# IME3_ICONT register map
Vendor: Texas Instruments
Peripheral module from a debugger description file (folder DRA75x_DRA74x).
Registers are 32-bit, read-write, no defined reset value unless marked. A register's access mark holds for its fields unless they carry their own. Offsets are as the file gives them; lines under a group give offsets from that group; [hi:lo] are bit positions; {n}, {i} and the like mark numbered series; 'fields as' and 'values as' point back to an identical list; <NAME> marks a mode.

## IME3_ICONT
0x00 IME3_REVISION ro — IP Revision Identifier (X.Y.R) Used by software to track features, bugs, and compatibility
  [31:0] REVISION — IP Revision
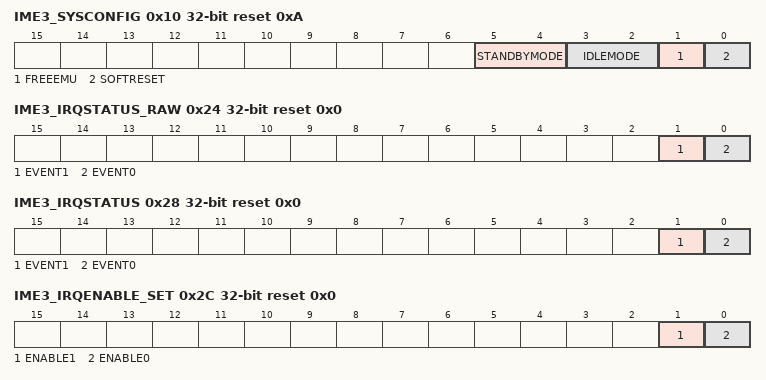
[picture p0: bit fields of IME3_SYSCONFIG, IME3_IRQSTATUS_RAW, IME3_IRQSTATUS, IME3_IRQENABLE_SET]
0x10 IME3_SYSCONFIG access per field reset 0xA — Clock management configuration
  [5:4] STANDBYMODE ro — Configuration of the local initiator state management mode. By definition, initiator may generate read/write transaction as long as it is out of STANDBY state.
    0=Force-standby mode: local initiator is unconditionally placed in standby state. Backup mode, for debug only.
  [3:2] IDLEMODE rw — Configuration of the local target state management mode. By definition, target can handle read/write transaction as long as it is out of IDLE state.
    0=Force-idle mode: local target's idle state follows (acknowledges) the system's idle requests unconditionally, that is, regardless of the IP module's internal requirements. Backup mode, for debug only.; 1=no (No-idle mode: local target never enters idle state. Backup mode, for debug only.); 2=Smart-idle mode: local target's idle state eventually follows (acknowledges) the system's idle requests, depending on the IP module's internal requirements. IP module shall not generate (IRQ- or DMA-request-related) wakeup events.; 3=smartwakeup (Smart-idle wakeup-capable mode: local target's idle state eventually follows (acknowledges) the system's idle requests, depending on the IP module's internal requirements. IP module may generate (IRQ- or DMA-request-related) wakeup events when in idle state. Mode is only relevant if the appropriate IP module 'swakeup' output(s) is (are) implemented.)
  [1] FREEEMU ro — Sensitivity to emulation (debug) suspend input signal.
    1=insensitive (IP module is not sensitive to emulation suspend)
  [0] SOFTRESET rw — Software reset. (Optional)
    0=done (Reset done, no pending action); 0=No_action; 1=pending (Initiate software reset); 1=Reset_(software_or_other)_ongoing
0x20 IME3_IRQ_EOI wo reset 0x0 — End Of Interrupt number specification
  [31:0] RESERVED — Write value should be zero.
0x24 IME3_IRQSTATUS_RAW access not given reset 0x0 — Per-event raw interrupt status vector, line #0. Raw status is set even if event is not enabled. Write 1 to set the (raw) status, mostly for debug.
  [1] EVENT1 — Settable raw status for event #1 (Gen_It) (access RW W1toSet)
    0=noevent (No action); 0=pending (No event pending); 1=set (Event pending); 1=Set_event_(debug)
  [0] EVENT0 — Settable raw status for event #0 (End_Pgm) (access RW W1toSet)
    values as EVENT1
0x28 IME3_IRQSTATUS access not given reset 0x0 — Per-event 'enabled' interrupt status vector, line #0. Enabled status is not set unless event is enabled. Write 1 to clear the status after interrupt has been serviced (raw status gets cleared, that is, even if not enabled).
  [1] EVENT1 — Clearable, enabled status for event #1 (Gen_it) (access RW W1toClr)
    0=noevent (No action); 0=pending (No (enabled) event pending); 1=clear (Event pending); 1=Clear_(raw)_event
  [0] EVENT0 — Clearable, enabled status for event #0 (End_Pgm) (access RW W1toClr)
    values as EVENT1
0x2C IME3_IRQENABLE_SET access not given reset 0x0 — Per-event interrupt enable bit vector, line #0. Write 1 to set (enable interrupt). Readout equal to corresponding _CLR register.
  [1] ENABLE1 — Enable for event #1 (Gen_It) (access RW W1toSet)
    0=disabled (No action); 0=Interrupt_disabled_(masked); 1=enabled (Interrupt enabled); 1=Enable_interrupt
  [0] ENABLE0 — Enable for event #0 (End_Pgm) (access RW W1toSet)
    values as ENABLE1
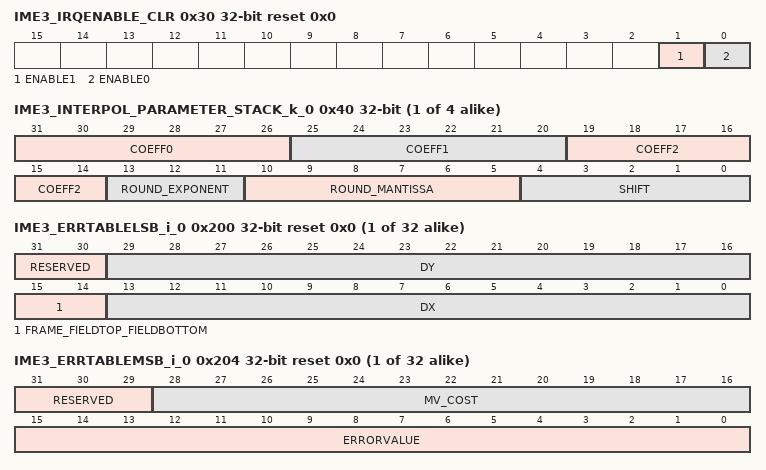
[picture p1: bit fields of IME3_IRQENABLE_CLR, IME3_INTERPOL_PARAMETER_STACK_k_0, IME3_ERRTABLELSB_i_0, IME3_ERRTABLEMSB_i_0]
0x30 IME3_IRQENABLE_CLR access not given reset 0x0 — Per-event interrupt enable bit vector, line #0. Write 1 to clear (disable interrupt). Readout equal to corresponding _SET register.
  [1] ENABLE1 — Enable for event #1 (Gen_It) (access RW W1toClr)
    0=disabled (No action); 0=Interrupt_disabled_(masked); 1=enabled (Interrupt enabled); 1=Disable_interrupt
  [0] ENABLE0 — Enable for event #0 (End_Pgm) (access RW W1toClr)
    values as ENABLE1
{0x40+4i} IME3_INTERPOL_PARAMETER_STACK_k_{i} (i=0..3) — Interpolation Filter Pass Configuration
  [31:26] COEFF0 — Coefficient vector
  [25:20] COEFF1 — Coefficient vector
  [19:14] COEFF2 — Coefficient vector
  [13:11] ROUND_EXPONENT — Rounding value - shift part
  [10:5] ROUND_MANTISSA — Rounding value - data part
  [4:0] SHIFT — Shift value
{0x80+4i} IME3_PARAMETERSTACK_i_{i} (i=0..31) — Parameter Stack register 0 to 31 (32-bit wide). Contains parameters used by program to control the IME3 units.
  [31:0] PARAMSTACKN — Parameter N of 0 to 31
{0x100+4i} IME3_CURRENTBLOCK_l_{i} (i=0..63) — Current Macroblock : 16 lines of 16 bytes containing the Current MacroBlock for SAD computation.
  [31:0] CURRENTBLOCKWORD — Current MacroBlock for SAD calculation
{0x200+8i} IME3_ERRTABLELSB_i_{i} access per field reset 0x0 (reset mask 0xC000C000) (i=0..31) — Error Table : Register File for SAD computation final errors. Each entry comprises a 16-bit error field, and 2 14-bit coordinate fields (dx and dy).
  [31:30] RESERVED ro — Read returns 0
  [29:16] DY rw — dy coordinate field
  [15:14] FRAME_FIELDTOP_FIELDBOTTOM ro — Read returns 0
  [13:0] DX rw — dx coordinate field
{0x204+8i} IME3_ERRTABLEMSB_i_{i} access per field reset 0x0 (reset mask 0xFFFF0000) (i=0..31) — Error Table : Register File for SAD computation final errors. Each entry comprises a 16-bit error field, and 2 14-bit coordinate fields (dx and dy).
  [31:29] RESERVED ro — Read returns 0
  [28:16] MV_COST ro
  [15:0] ERRORVALUE rw — error field
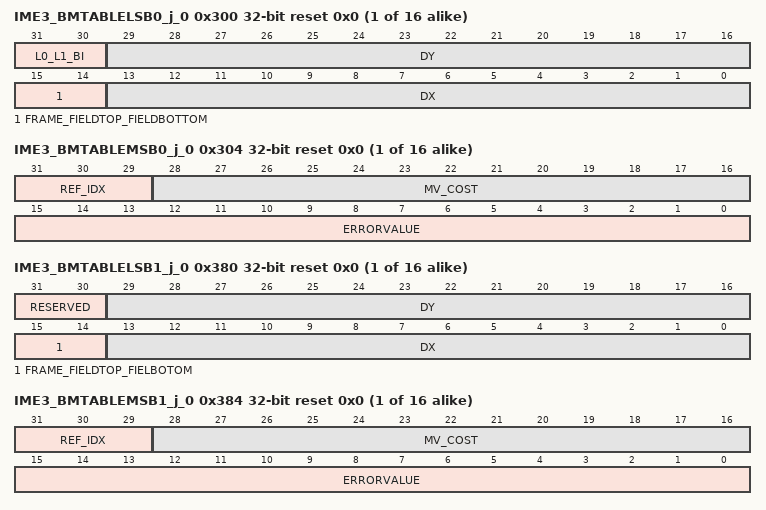
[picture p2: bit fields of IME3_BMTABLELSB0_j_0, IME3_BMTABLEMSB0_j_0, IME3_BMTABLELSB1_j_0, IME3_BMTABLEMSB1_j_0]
{0x300+8i} IME3_BMTABLELSB0_j_{i} access per field reset 0x0 (reset mask 0xC000) (i=0..15) — Best Match Table : register file contain result of Error Table comparisson. BestMatchTable0 is for List0 computation. BestMatchTable1 is for List1 computation. Each Best Match Table position correspond to one sub-partition of the 16x16 MB. For 1-MV type computation, best match is stored in entry 0 For 16-MV stored computation, each entry correspond to one of the 16 4x4 partitions. Otherwise, entries 0 to 8 are used.
  [31:30] L0_L1_BI rw
  [29:16] DY rw — dy coordinate field
  [15:14] FRAME_FIELDTOP_FIELDBOTTOM ro — Read returns 0
  [13:0] DX rw — dx coordinate field
{0x304+8i} IME3_BMTABLEMSB0_j_{i} access per field reset 0x0 (reset mask 0x1FFF0000) (i=0..15) — Best Match Table : register file contain result of Error Table comparisson. BestMatchTable0 is for List0 computation. BestMatchTable1 is for List1 computation. Each Best Match Table position correspond to one sub-partition of the 16x16 MB. For 1-MV type computation, best match is stored in entry 0 For 16-MV stored computation, each entry correspond to one of the 16 4x4 partitions. Otherwise, entries 0 to 8 are used.
  [31:29] REF_IDX rw — Reference Frame Idx, provided by software
  [28:16] MV_COST ro
  [15:0] ERRORVALUE rw — error field
{0x380+8i} IME3_BMTABLELSB1_j_{i} access per field reset 0x0 (reset mask 0xC000C000) (i=0..15) — Best Match Table : register file contain result of Error Table comparisson. BestMatchTable0 is for List0 computation. BestMatchTable1 is for List1 computation. Each Best Match Table position correspond to one sub-partition of the 16x16 MB. For 1-MV type computation, best match is stored in entry 0 For 16-MV stored computation, each entry correspond to one of the 16 4x4 partitions. Otherwise, entries 0 to 8 are used.
  [31:30] RESERVED ro — Read returns 0
  [29:16] DY rw — dy coordinate field
  [15:14] FRAME_FIELDTOP_FIELBOTOM ro — Read returns 0
  [13:0] DX rw — dx coordinate field
{0x384+8i} IME3_BMTABLEMSB1_j_{i} access per field reset 0x0 (reset mask 0x1FFF0000) (i=0..15) — Best Match Table : register file contain result of Error Table comparisson. BestMatchTable0 is for List0 computation. BestMatchTable1 is for List1 computation. Each Best Match Table position correspond to one sub-partition of the 16x16 MB. For 1-MV type computation, best match is stored in entry 0 For 16-MV stored computation, each entry correspond to one of the 16 4x4 partitions. Otherwise, entries 0 to 8 are used.
  fields as IME3_BMTABLEMSB0_j_0
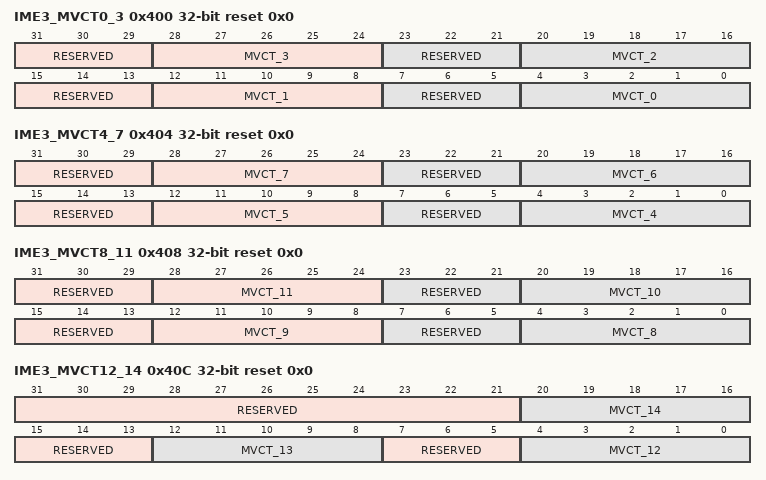
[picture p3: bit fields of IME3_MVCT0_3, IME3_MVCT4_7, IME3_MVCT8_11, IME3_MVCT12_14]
0x400 IME3_MVCT0_3 access per field reset 0x0 (reset mask 0xE0E0E0E0) — MV Cost Table
  [31:29] RESERVED ro — Read returns 0
  [8n+4:8n] MVCT_{n} rw (n=0..3) — MV Cost Table {n}
  [23:21] RESERVED ro — Read returns 0
  [15:13] RESERVED ro — Read returns 0
  [7:5] RESERVED ro — Read returns 0
0x404 IME3_MVCT4_7 access per field reset 0x0 (reset mask 0xE0E0E0E0) — MV Cost Table
  [31:29] RESERVED ro — Read returns 0
  [8n-28:8n-32] MVCT_{n} rw (n=4..7) — MV Cost Table {n}
  [23:21] RESERVED ro — Read returns 0
  [15:13] RESERVED ro — Read returns 0
  [7:5] RESERVED ro — Read returns 0
0x408 IME3_MVCT8_11 access per field reset 0x0 (reset mask 0xE0E0E0E0) — MV Cost Table
  [31:29] RESERVED ro — Read returns 0
  [8n-60:8n-64] MVCT_{n} rw (n=8..11) — MV Cost Table {n-8}
  [23:21] RESERVED ro — Read returns 0
  [15:13] RESERVED ro — Read returns 0
  [7:5] RESERVED ro — Read returns 0
0x40C IME3_MVCT12_14 access per field reset 0x0 (reset mask 0xFFE0E0E0) — MV Cost Table
  [31:21] RESERVED ro — Read returns 0
  [20:16] MVCT_14 rw — MV Cost Table 14
  [15:13] RESERVED ro — Read returns 0
  [12:8] MVCT_13 rw — MV Cost Table 13
  [7:5] RESERVED ro — Read returns 0
  [4:0] MVCT_12 rw — MV Cost Table 12
0x410 IME3_VEC_VAR_HOR_LO — horizontal vector variable (lower bits)
  [31:0] VEC_VAR_LO
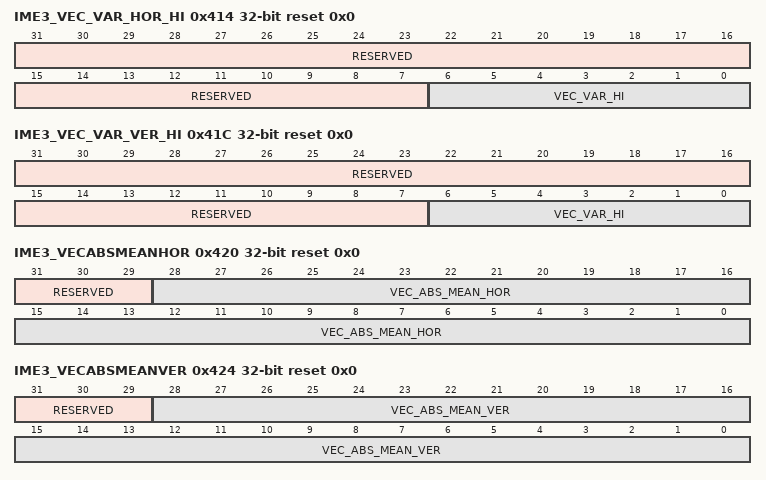
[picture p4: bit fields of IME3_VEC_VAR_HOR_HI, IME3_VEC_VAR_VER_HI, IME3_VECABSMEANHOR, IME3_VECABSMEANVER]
0x414 IME3_VEC_VAR_HOR_HI access per field reset 0x0 (reset mask 0xFFFFFF80) — horizontal vector variable (higher bits)
  [31:7] RESERVED ro — Read returns 0
  [6:0] VEC_VAR_HI rw
0x418 IME3_VEC_VAR_VER_LO — vertical vector variable (lower bits)
  [31:0] VEC_VAR_LO
0x41C IME3_VEC_VAR_VER_HI access per field reset 0x0 (reset mask 0xFFFFFF80) — vertical vector variable (higher bits)
  [31:7] RESERVED ro — Read returns 0
  [6:0] VEC_VAR_HI rw
0x420 IME3_VECABSMEANHOR access per field reset 0x0 (reset mask 0xE0000000)
  [31:29] RESERVED ro — Read returns 0
  [28:0] VEC_ABS_MEAN_HOR rw — Accumulates |BMT0[0].dx|
0x424 IME3_VECABSMEANVER access per field reset 0x0 (reset mask 0xE0000000)
  [31:29] RESERVED ro — Read returns 0
  [28:0] VEC_ABS_MEAN_VER rw — Accumulates |BMT0[0].dy|
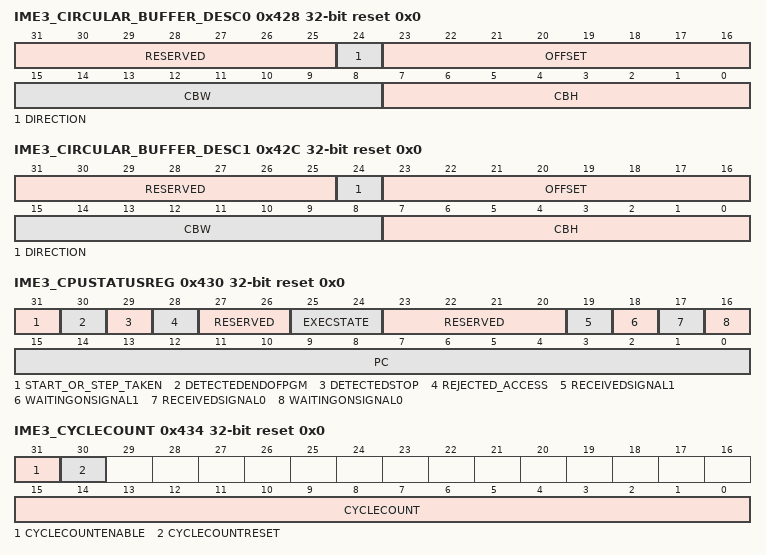
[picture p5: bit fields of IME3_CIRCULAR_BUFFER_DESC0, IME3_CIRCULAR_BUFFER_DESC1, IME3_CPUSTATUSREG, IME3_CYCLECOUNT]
0x428 IME3_CIRCULAR_BUFFER_DESC0 access per field reset 0x0 (reset mask 0xFE000000) — Circular Buffer 0
  [31:25] RESERVED ro — Read returns 0
  [24] DIRECTION rw — Horizontal or Vertical Circularity
  [23:16] OFFSET rw — In MBs
  [15:8] CBW rw — Circular Buffer Width, in MBs
  [7:0] CBH rw — Circular Buffer Height, in MBs
0x42C IME3_CIRCULAR_BUFFER_DESC1 access per field reset 0x0 (reset mask 0xFE000000) — Circular Buffer 1
  fields as IME3_CIRCULAR_BUFFER_DESC0
0x430 IME3_CPUSTATUSREG access per field reset 0x0 — CPU Status Register provides information on the progress of the CPU execution
  [31] START_OR_STEP_TAKEN rw — Set to 1 when Step() Local Interconnect command is received. Set to 1 when SyncBox new task command is received. Set to 0 when Local Interconnect writes 0 to this bit field.
  [30] DETECTEDENDOFPGM ro — This bit is set to '1' when in Debug mode, an EndOfPgm instruction or the last instruction of ProgramBuffer has been reached.
  [29] DETECTEDSTOP ro — This bit is set to '1' when a Stop() command is received. This bit is set to '0' when a Step() command is received.
  [28] REJECTED_ACCESS ro — Set when a Local Interconnect read to the Program Memory, or an Local Interconnect write are perfromed while the IME3 is still in the EXECUTING state. Reset when the IME3 is is the INITIALIZED or COMPLETED state and a step command is received.
  [27:26] RESERVED ro — Read returns 0
  [25:24] EXECSTATE ro — 0x0 =&gt; Initialized 0x1 =&gt; Halted 0x2 =&gt; Exectuting 0x3 =&gt; Completed
  [23:20] RESERVED ro — Read returns 0
  [19] RECEIVEDSIGNAL1 ro — Indicates that module has received a Local Interconnect Signal1 Command. Reset by Wait_On_Signal_1() api.
  [18] WAITINGONSIGNAL1 ro — Indicates that module is waiting for Local Interconnect Signal1 Command. Set by Wait_On_Signal_1() api. Reset when ReceivedSignal0 is set (by Signal1 Local Interconnect command).
  [17] RECEIVEDSIGNAL0 ro — Indicates that module has received a Local Interconnect Signal0 Command. Reset by Wait_On_Signal_0() api.
  [16] WAITINGONSIGNAL0 ro — Indicates that module is waiting for Local Interconnect Signal0 Command. Set by Wait_On_Signal_0() api. Reset when ReceivedSignal0 is set (by Signal0 Local Interconnect command).
  [15:0] PC ro — Address of the instruction currently issued.
0x434 IME3_CYCLECOUNT access not given reset 0x0 — Cycle count register
  [31] CYCLECOUNTENABLE rw — When set to 1, cycle counting is enabled. When set to 0, cycle counting is disabled.
  [30] CYCLECOUNTRESET — Writing 0 results in no effect. Writing 1 results in clearing CycleCount to 0. Always read as 0. (access W W1toClr)
  [15:0] CYCLECOUNT ro — Incremets at each cycle if cycleCountEnable equals 1 and if CpuState is EXECUTING. Reset when writing 1 to bit 30 (CycleCountReset) Reset upon receiving a Stop() Local Interconnect command.
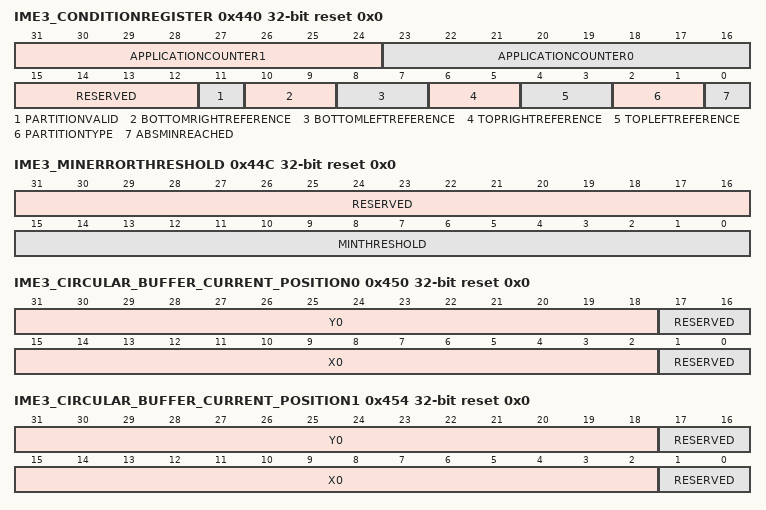
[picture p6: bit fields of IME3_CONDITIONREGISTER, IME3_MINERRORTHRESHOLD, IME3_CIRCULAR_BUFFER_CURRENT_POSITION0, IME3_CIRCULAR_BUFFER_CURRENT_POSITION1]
0x440 IME3_CONDITIONREGISTER access per field reset 0x0 (reset mask 0xF000) — Absolute Minimum Reached bit register, used in Mcomp() operator.
  [31:24] APPLICATIONCOUNTER1 rw — Counter 1
  [23:16] APPLICATIONCOUNTER0 rw — Counter 0
  [15:12] RESERVED ro — Read returns 0
  [11] PARTITIONVALID rw — Reset by ClearStatus()
  [10:9] BOTTOMRIGHTREFERENCE rw — L0, L1, Bi
  [8:7] BOTTOMLEFTREFERENCE rw — L0, L1, Bi
  [6:5] TOPRIGHTREFERENCE rw — L0, L1, Bi
  [4:3] TOPLEFTREFERENCE rw — L0, L1, Bi
  [2:1] PARTITIONTYPE rw — 16x16, 16x8, 8x16, 8x8
  [0] ABSMINREACHED rw — Abs Min Reached bit, in Mcomp block.
0x44C IME3_MINERRORTHRESHOLD access per field reset 0x0 (reset mask 0xFFFF0000) — Minimum Error Threshold register, used in Mcomp() operator.
  [31:16] RESERVED ro — read returns 0.
  [15:0] MINTHRESHOLD rw — Min Threshold value in Mcomp() block.
0x450 IME3_CIRCULAR_BUFFER_CURRENT_POSITION0 access per field reset 0x0 (reset mask 0x30003) — Current position in the circular buffer
  [31:18] Y0 rw — Position of colocated MB in the circular buffer when origin is taken at top left corner of circular buffer (Y coordinate, pixel precision).
  [17:16] RESERVED ro — Read returns 0
  [15:2] X0 rw — Position of colocated MB in the circular buffer when origin is taken at top left corner of circular buffer (X coordinate, pixel precision).
  [1:0] RESERVED ro — Read returns 0
0x454 IME3_CIRCULAR_BUFFER_CURRENT_POSITION1 access per field reset 0x0 (reset mask 0x30003)
  [31:18] Y0 rw — Position of colocated MB in the circular buffer when origin is taken at top left corner of circular buffer (Y coordinate, pixel precision)
  [17:16] RESERVED ro — Read returns 0
  [15:2] X0 rw — Position of colocated MB in the circular buffer when origin is taken at top left corner of circular buffer (X coordinate, pixel precision)
  [1:0] RESERVED ro — Read returns 0
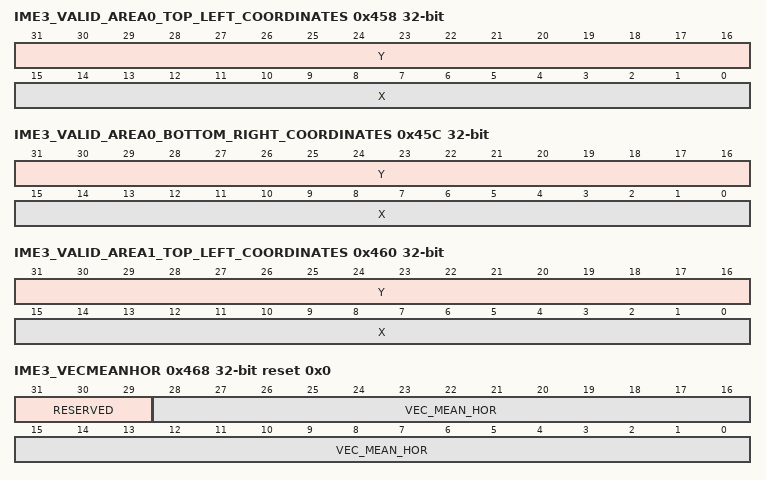
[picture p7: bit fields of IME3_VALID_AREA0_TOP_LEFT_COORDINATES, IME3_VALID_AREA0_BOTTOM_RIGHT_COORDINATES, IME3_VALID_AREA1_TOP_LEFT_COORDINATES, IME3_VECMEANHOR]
0x458 IME3_VALID_AREA0_TOP_LEFT_COORDINATES — Top left coordinates
  [31:16] Y — Valid area top left limit in the circular buffer (Y coordinate, quarter pixel precision)
  [15:0] X — Valid area top left limit in the circular buffer (X coordinate, quarter pixel precision)
0x45C IME3_VALID_AREA0_BOTTOM_RIGHT_COORDINATES — Bottom right coordinates
  [31:16] Y — Valid area bottom right limit in the circular buffer (Y coordinate, quarter pixel precision)
  [15:0] X — Valid area top left limit in the circular buffer (X coordinate, quarter pixel precision)
0x460 IME3_VALID_AREA1_TOP_LEFT_COORDINATES — Top left coordinates
  fields as IME3_VALID_AREA0_BOTTOM_RIGHT_COORDINATES
0x468 IME3_VECMEANHOR access per field reset 0x0 (reset mask 0xE0000000)
  [31:29] RESERVED ro — Read returns 0
  [28:0] VEC_MEAN_HOR rw — Accumulates BMT0[0].dx
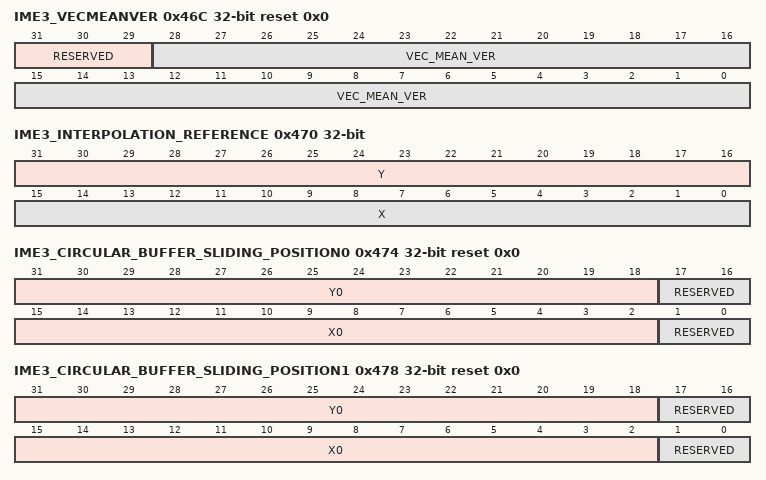
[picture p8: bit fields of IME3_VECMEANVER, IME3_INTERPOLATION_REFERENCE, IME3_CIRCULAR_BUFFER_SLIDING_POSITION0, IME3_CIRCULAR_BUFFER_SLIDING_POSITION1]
0x46C IME3_VECMEANVER access per field reset 0x0 (reset mask 0xE0000000)
  [31:29] RESERVED ro — Read returns 0
  [28:0] VEC_MEAN_VER rw — Accumulates BMT0[0].dy
0x470 IME3_INTERPOLATION_REFERENCE — The Interpol Reference is the MV based on which the last interpolation has been performed. This register is updated by the Interpol APIs, and is later used for computing the MVCost and addresses when manipulating pixels from the interpolated planes.
  [31:16] Y — This is the 'y' coordinate of the {0,0} point of the interpol planes.
  [15:0] X — x coordinate for the origin point of the interpolation. This is the 'x' coordinate of the {0,0} point of the interpol planes. The Interpol planes contain points starting at {-1,-1} and ending at {i, j} with i=7 or i=15 and j=7 or j=15 depending on the interpol size.
0x474 IME3_CIRCULAR_BUFFER_SLIDING_POSITION0 access per field reset 0x0 (reset mask 0x30003)
  [31:18] Y0 rw — Position of colocated MB in the circular buffer (Y coordinate, pixel precision)
  [17:16] RESERVED ro — Read returns 0
  [15:2] X0 rw — Position of colocated MB in the circular buffer (X coordinate, pixel precision)
  [1:0] RESERVED ro — Read returns 0
0x478 IME3_CIRCULAR_BUFFER_SLIDING_POSITION1 access per field reset 0x0 (reset mask 0x30003)
  fields as IME3_CIRCULAR_BUFFER_SLIDING_POSITION0
0x1FFC IME3_COMMANDREG wo reset 0x0 — IME3 command register: a write to this register decodes a command, a read returns 0.
  [31:0] COMMAND — A write decodes a command, a read returns 0. 0x1 -&gt; Step() 0x2 -&gt; StopSeq() 0x3 -&gt; DbgEnable() 0x4 -&gt; DbgDisable()
{0x2000+4i} IME3_PROGRAMBUFFER_m_{i} (i=0..2047) — Program Memory 32-bit word
  [31:0] PROGRAM_MEMORY_WORD — Word N of 1024
